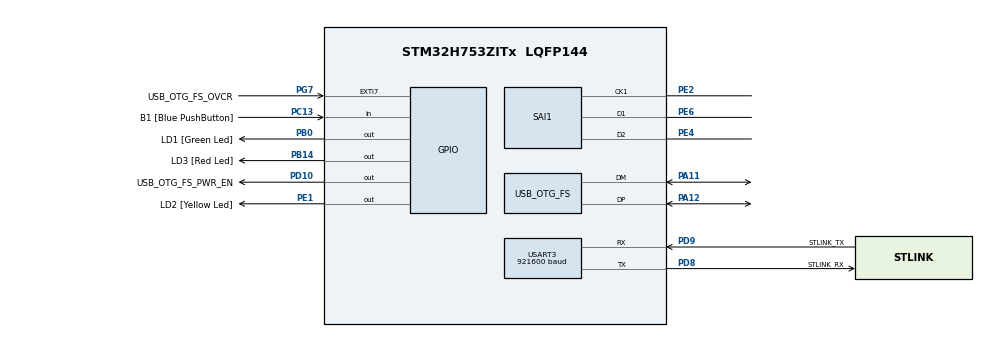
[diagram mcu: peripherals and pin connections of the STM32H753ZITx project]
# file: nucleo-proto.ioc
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CORTEX_M7.CPU_DCache=Disabled
CORTEX_M7.CPU_ICache=Enabled
CORTEX_M7.MPU_Control=__NULL
Dma.Request0=SAI1_A
Dma.SAI1_A.0.Direction=DMA_PERIPH_TO_MEMORY
Dma.SAI1_A.0.EventEnable=DISABLE
Dma.SAI1_A.0.FIFOMode=DMA_FIFOMODE_DISABLE
Dma.SAI1_A.0.Instance=DMA1_Stream0
Dma.SAI1_A.0.MemDataAlignment=DMA_MDATAALIGN_HALFWORD
Dma.SAI1_A.0.MemInc=DMA_MINC_ENABLE
Dma.SAI1_A.0.Mode=DMA_CIRCULAR
Dma.SAI1_A.0.PeriphDataAlignment=DMA_PDATAALIGN_HALFWORD
Dma.SAI1_A.0.PeriphInc=DMA_PINC_DISABLE
Dma.SAI1_A.0.Polarity=HAL_DMAMUX_REQ_GEN_RISING
Dma.SAI1_A.0.Priority=DMA_PRIORITY_VERY_HIGH
Dma.SAI1_A.0.RequestNumber=1
Dma.SAI1_A.0.SignalID=NONE
Dma.SAI1_A.0.SyncEnable=DISABLE
Dma.SAI1_A.0.SyncPolarity=HAL_DMAMUX_SYNC_NO_EVENT
Dma.SAI1_A.0.SyncRequestNumber=1
Dma.SAI1_A.0.SyncSignalID=NONE
Mcu.Family=STM32H7
Mcu.Name=STM32H753ZITx
Mcu.Package=LQFP144
NVIC.DMA1_Stream0_IRQn=true\:1\:0\:true\:false\:true\:false\:true\:true
NVIC.OTG_FS_IRQn=true\:5\:0\:true\:false\:true\:false\:true\:true
NVIC.PriorityGroup=NVIC_PRIORITYGROUP_4
NVIC.SAI1_IRQn=true\:2\:0\:true\:false\:true\:true\:true\:true
PA1.Signal=ETH_REF_CLK
PA11.Mode=Device_Only
PA11.Signal=USB_OTG_FS_DM
PA12.Mode=Device_Only
PA12.Signal=USB_OTG_FS_DP
PA2.Signal=ETH_MDIO
PA7.Signal=ETH_CRS_DV
PA8.Signal=USB_OTG_FS_SOF
PA9.Signal=USB_OTG_FS_VBUS
PB0.GPIO_Label=LD1 [Green Led]
PB0.Signal=GPIO_Output
PB13.Signal=ETH_TXD1
PB14.GPIO_Label=LD3 [Red Led]
PB14.Signal=GPIO_Output
PC1.Signal=ETH_MDC
PC13.GPIO_Label=B1 [Blue PushButton]
PC13.Signal=GPIO_Input
PC14-OSC32_IN\ (OSC32_IN).Mode=LSE-External-Oscillator
PC14-OSC32_IN\ (OSC32_IN).Signal=RCC_OSC32_IN
PC15-OSC32_OUT\ (OSC32_OUT).Mode=LSE-External-Oscillator
PC15-OSC32_OUT\ (OSC32_OUT).Signal=RCC_OSC32_OUT
PC4.Signal=ETH_RXD0
PC5.Signal=ETH_RXD1
PD10.GPIO_Label=USB_OTG_FS_PWR_EN
PD10.Signal=GPIO_Output
PD8.GPIO_Label=STLINK_RX
PD8.Mode=Asynchronous
PD8.Signal=USART3_TX
PD9.GPIO_Label=STLINK_TX
PD9.Mode=Asynchronous
PD9.Signal=USART3_RX
PDM2PCM.CHANNEL1_output_samples_number=48
PE1.GPIO_Label=LD2 [Yellow Led]
PE1.Signal=GPIO_Output
PE2.Mode=PDM_Master_Mode_CK1
PE2.Signal=SAI1_CK1
PE4.Mode=3_4_MicroPhones
PE4.Signal=SAI1_D2
PE6.Mode=PDM_Master_Mode_CK1
PE6.Signal=SAI1_D1
PG11.Signal=ETH_TX_EN
PG13.Signal=ETH_TXD0
PG7.GPIO_Label=USB_OTG_FS_OVCR
PG7.Signal=GPXTI7
PH0-OSC_IN\ (PH0).Mode=HSE-External-Clock-Source
PH0-OSC_IN\ (PH0).Signal=RCC_OSC_IN
PH1-OSC_OUT\ (PH1).Signal=RCC_OSC_OUT
ProjectManager.HeapSize=0x200
ProjectManager.StackSize=0x2000
ProjectManager.TargetToolchain=STM32CubeIDE
RCC.ADCFreq_Value=16125000
RCC.APB1Freq_Value=120000000
RCC.APB2Freq_Value=120000000
RCC.APB3Freq_Value=120000000
RCC.APB4Freq_Value=120000000
RCC.CortexFreq_Value=480000000
RCC.D1PPRE=RCC_APB3_DIV2
RCC.D2PPRE1=RCC_APB1_DIV2
RCC.D2PPRE2=RCC_APB2_DIV2
RCC.D3PPRE=RCC_APB4_DIV2
RCC.DIVM1=1
RCC.DIVM3=2
RCC.DIVN1=120
RCC.DIVN3=49
RCC.DIVP3=4
RCC.DIVQ1=4
RCC.HCLKFreq_Value=240000000
RCC.HPRE=RCC_HCLK_DIV2
RCC.HSE_VALUE=8000000
RCC.PLL2FRACN=0
RCC.PLL3FRACN=1245
RCC.PLLFRACN=0
RCC.PLLSourceVirtual=RCC_PLLSOURCE_HSE
RCC.PWR_Regulator_Voltage_Scale=PWR_REGULATOR_VOLTAGE_SCALE0
RCC.ProductRev=revV
RCC.SAI1CLockSelection=RCC_SAI1CLKSOURCE_PLL3
RCC.SYSCLKFreq_VALUE=480000000
RCC.SYSCLKSource=RCC_SYSCLKSOURCE_PLLCLK
RCC.USBCLockSelection=RCC_USBCLKSOURCE_HSI48
RCC.USBFreq_Value=48000000
SAI1.Activation=ENABLE
SAI1.AudioFrequency-PDM_Master_Mode_CK1=SAI_AUDIO_FREQUENCY_192K
SAI1.DataSize-PDM_Master_Mode_CK1=SAI_DATASIZE_16
SAI1.ErrorAudioFreq-PDM_Master_Mode_CK1=0.0 %
SAI1.FIFOThreshold-PDM_Master_Mode_CK1=SAI_FIFOTHRESHOLD_1QF
SAI1.FSPolarity-PDM_Master_Mode_CK1=SAI_FS_ACTIVE_HIGH
SAI1.FirstBit-PDM_Master_Mode_CK1=SAI_FIRSTBIT_LSB
SAI1.FrameLength-PDM_Master_Mode_CK1=32
SAI1.Instance-PDM_Master_Mode_CK1=SAI$Index_Block_A
SAI1.MClockEnable-PDM_Master_Mode_CK1=SAI_MASTERCLOCK_DISABLE
SAI1.NoDivider-PDM_Master_Mode_CK1=SAI_MASTERDIVIDER_ENABLE
SAI1.RealAudioFreq-PDM_Master_Mode_CK1=191.999 KHz
SAI1.SlotActive-PDM_Master_Mode_CK1=0x00000003
SAI1.SlotNumber-PDM_Master_Mode_CK1=2
SAI1.VirtualMode-PDM_Master_Mode_CK1=VM_MASTER
SAI1.VirtualProtocol-PDM_Master_Mode_CK1=VM_PDM_PROTOCOL
SAI1.VirtualSlotActive-PDM_Master_Mode_CK1=SAI_SLOT_USERSETTING
SAI1.VirtualSlotActive0-PDM_Master_Mode_CK1=true
SAI1.VirtualSlotActive1-PDM_Master_Mode_CK1=true
SAI1.VirtualSlotActive2-PDM_Master_Mode_CK1=true
SAI1.VirtualSlotActive3-PDM_Master_Mode_CK1=true
USART3.BaudRate=921600
USART3.VirtualMode-Asynchronous=VM_ASYNC
USB_DEVICE.CLASS_NAME_FS=CDC
USB_DEVICE.VirtualMode-CDC_FS=Cdc
USB_DEVICE.VirtualModeFS=Cdc_FS
USB_OTG_FS.VirtualMode=Device_Only
VP_CRC_VS_CRC.Mode=CRC_Activate
VP_PDM2PCM_VS_PDM2PCM.Mode=PDM2PCM_Channel
VP_RCC_USB.Mode=USB_FS
VP_USB_DEVICE_VS_USB_DEVICE_CDC_FS.Mode=CDC_FS
board=NUCLEO-H753ZI

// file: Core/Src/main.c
/* USER CODE BEGIN Header */
/**
  ******************************************************************************
  * @file           : main.c
  * @brief          : Main program body
  ******************************************************************************
  * @attention
  *
  * Copyright (c) 2026 STMicroelectronics.
  * All rights reserved.
  *
  * This software is licensed under terms that can be found in the LICENSE file
  * in the root directory of this software component.
  * If no LICENSE file comes with this software, it is provided AS-IS.
  *
  ******************************************************************************
  */
/* USER CODE END Header */
#include "main.h"
#include "crc.h"
#include "dma.h"
#include "pdm2pcm.h"
#include "sai.h"
#include "usart.h"
#include "usb_device.h"
#include "gpio.h"

/* USER CODE BEGIN Includes */
#include "app_main.h"
/* USER CODE END Includes */

void SystemClock_Config(void);

int main(void)
{

  /* Enable I-Cache---------------------------------------------------------*/
  SCB_EnableICache();

  /* MCU Configuration--------------------------------------------------------*/

  /* Reset of all peripherals, Initializes the Flash interface and the Systick. */
  HAL_Init();

  /* Configure the system clock */
  SystemClock_Config();

  /* Initialize all configured peripherals */
  MX_GPIO_Init();
  MX_DMA_Init();
  MX_SAI1_Init();
  MX_USART3_UART_Init();
  MX_CRC_Init();
  MX_PDM2PCM_Init();
  MX_USB_DEVICE_Init();
  /* USER CODE BEGIN 2 */
  app_init();
  /* USER CODE END 2 */

  /* Infinite loop */
  while (1)
  {

    /* USER CODE BEGIN 3 */
    app_loop();
  }
  /* USER CODE END 3 */
}

void SystemClock_Config(void)
{
  RCC_OscInitTypeDef RCC_OscInitStruct = {0};
  RCC_ClkInitTypeDef RCC_ClkInitStruct = {0};
  RCC_CRSInitTypeDef RCC_CRSInitStruct = {0};

  /** Supply configuration update enable
  */
  HAL_PWREx_ConfigSupply(PWR_LDO_SUPPLY);

  /** Configure the main internal regulator output voltage
  */
  __HAL_PWR_VOLTAGESCALING_CONFIG(PWR_REGULATOR_VOLTAGE_SCALE1);

  while(!__HAL_PWR_GET_FLAG(PWR_FLAG_VOSRDY)) {}

  __HAL_RCC_SYSCFG_CLK_ENABLE();
  __HAL_PWR_VOLTAGESCALING_CONFIG(PWR_REGULATOR_VOLTAGE_SCALE0);

  while(!__HAL_PWR_GET_FLAG(PWR_FLAG_VOSRDY)) {}

  /** Initializes the RCC Oscillators according to the specified parameters
  * in the RCC_OscInitTypeDef structure.
  */
  RCC_OscInitStruct.OscillatorType = RCC_OSCILLATORTYPE_HSI48|RCC_OSCILLATORTYPE_HSE;
  RCC_OscInitStruct.HSEState = RCC_HSE_BYPASS;
  RCC_OscInitStruct.HSI48State = RCC_HSI48_ON;
  RCC_OscInitStruct.PLL.PLLState = RCC_PLL_ON;
  RCC_OscInitStruct.PLL.PLLSource = RCC_PLLSOURCE_HSE;
  RCC_OscInitStruct.PLL.PLLM = 1;
  RCC_OscInitStruct.PLL.PLLN = 120;
  RCC_OscInitStruct.PLL.PLLP = 2;
  RCC_OscInitStruct.PLL.PLLQ = 4;
  RCC_OscInitStruct.PLL.PLLR = 2;
  RCC_OscInitStruct.PLL.PLLRGE = RCC_PLL1VCIRANGE_3;
  RCC_OscInitStruct.PLL.PLLVCOSEL = RCC_PLL1VCOWIDE;
  RCC_OscInitStruct.PLL.PLLFRACN = 0;
  if (HAL_RCC_OscConfig(&RCC_OscInitStruct) != HAL_OK)
  {
    Error_Handler();
  }

  /** Initializes the CPU, AHB and APB buses clocks
  */
  RCC_ClkInitStruct.ClockType = RCC_CLOCKTYPE_HCLK|RCC_CLOCKTYPE_SYSCLK
                              |RCC_CLOCKTYPE_PCLK1|RCC_CLOCKTYPE_PCLK2
                              |RCC_CLOCKTYPE_D3PCLK1|RCC_CLOCKTYPE_D1PCLK1;
  RCC_ClkInitStruct.SYSCLKSource = RCC_SYSCLKSOURCE_PLLCLK;
  RCC_ClkInitStruct.SYSCLKDivider = RCC_SYSCLK_DIV1;
  RCC_ClkInitStruct.AHBCLKDivider = RCC_HCLK_DIV2;
  RCC_ClkInitStruct.APB3CLKDivider = RCC_APB3_DIV2;
  RCC_ClkInitStruct.APB1CLKDivider = RCC_APB1_DIV2;
  RCC_ClkInitStruct.APB2CLKDivider = RCC_APB2_DIV2;
  RCC_ClkInitStruct.APB4CLKDivider = RCC_APB4_DIV2;

  if (HAL_RCC_ClockConfig(&RCC_ClkInitStruct, FLASH_LATENCY_4) != HAL_OK)
  {
    Error_Handler();
  }

  /** Enable the SYSCFG APB clock
  */
  __HAL_RCC_CRS_CLK_ENABLE();

  /** Configures CRS
  */
  RCC_CRSInitStruct.Prescaler = RCC_CRS_SYNC_DIV1;
  RCC_CRSInitStruct.Source = RCC_CRS_SYNC_SOURCE_USB2;
  RCC_CRSInitStruct.Polarity = RCC_CRS_SYNC_POLARITY_RISING;
  RCC_CRSInitStruct.ReloadValue = __HAL_RCC_CRS_RELOADVALUE_CALCULATE(48000000,1000);
  RCC_CRSInitStruct.ErrorLimitValue = 34;
  RCC_CRSInitStruct.HSI48CalibrationValue = 32;

  HAL_RCCEx_CRSConfig(&RCC_CRSInitStruct);
}

void Error_Handler(void)
{
  /* USER CODE BEGIN Error_Handler_Debug */
  __disable_irq();
  HAL_GPIO_WritePin(LD3_GPIO_Port, LD3_Pin, GPIO_PIN_SET);    /* red LED = error */
  while (1)
  {
  }
  /* USER CODE END Error_Handler_Debug */
}
